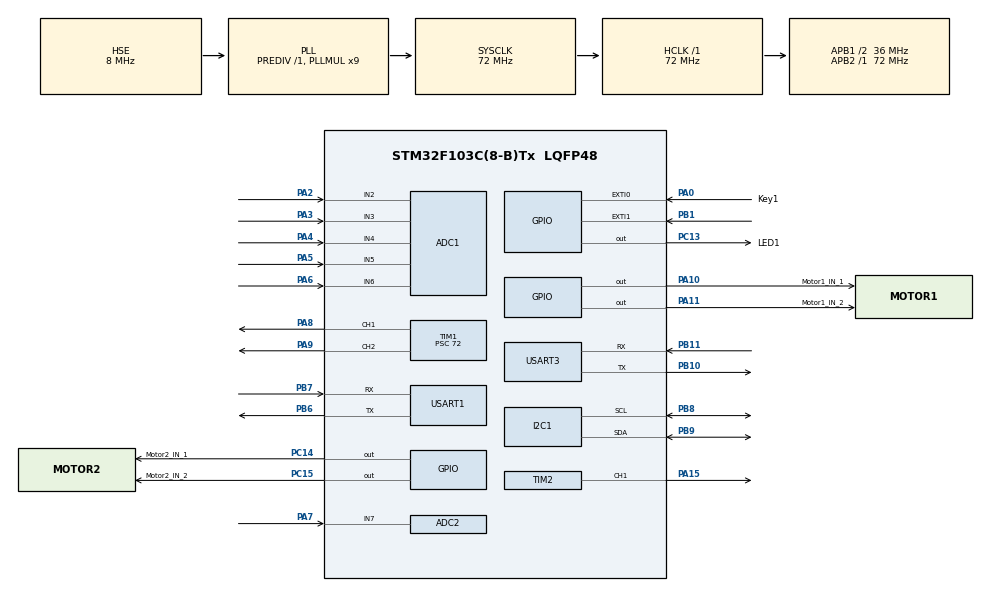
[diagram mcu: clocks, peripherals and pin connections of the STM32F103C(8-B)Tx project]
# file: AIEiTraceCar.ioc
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ADC1.Channel-1\#ChannelRegularConversion=ADC_CHANNEL_2
ADC1.Channel-2\#ChannelRegularConversion=ADC_CHANNEL_3
ADC1.Channel-3\#ChannelRegularConversion=ADC_CHANNEL_4
ADC1.Channel-4\#ChannelRegularConversion=ADC_CHANNEL_5
ADC1.Channel-5\#ChannelRegularConversion=ADC_CHANNEL_6
ADC1.ContinuousConvMode=ENABLE
ADC1.ExternalTrigConv=ADC_SOFTWARE_START
ADC1.NbrOfConversion=5
ADC1.NbrOfConversionFlag=1
ADC1.Rank-1\#ChannelRegularConversion=1
ADC1.Rank-2\#ChannelRegularConversion=2
ADC1.Rank-3\#ChannelRegularConversion=3
ADC1.Rank-4\#ChannelRegularConversion=4
ADC1.Rank-5\#ChannelRegularConversion=5
ADC1.SamplingTime-1\#ChannelRegularConversion=ADC_SAMPLETIME_1CYCLE_5
ADC1.SamplingTime-2\#ChannelRegularConversion=ADC_SAMPLETIME_1CYCLE_5
ADC1.SamplingTime-3\#ChannelRegularConversion=ADC_SAMPLETIME_1CYCLE_5
ADC1.SamplingTime-4\#ChannelRegularConversion=ADC_SAMPLETIME_1CYCLE_5
ADC1.SamplingTime-5\#ChannelRegularConversion=ADC_SAMPLETIME_1CYCLE_5
ADC1.master=1
ADC2.Channel-1\#ChannelRegularConversion=ADC_CHANNEL_7
ADC2.ContinuousConvMode=ENABLE
ADC2.NbrOfConversion=1
ADC2.NbrOfConversionFlag=1
ADC2.Rank-1\#ChannelRegularConversion=1
ADC2.SamplingTime-1\#ChannelRegularConversion=ADC_SAMPLETIME_1CYCLE_5
Dma.ADC1.1.Direction=DMA_PERIPH_TO_MEMORY
Dma.ADC1.1.Instance=DMA1_Channel1
Dma.ADC1.1.MemDataAlignment=DMA_MDATAALIGN_HALFWORD
Dma.ADC1.1.MemInc=DMA_MINC_ENABLE
Dma.ADC1.1.Mode=DMA_CIRCULAR
Dma.ADC1.1.PeriphDataAlignment=DMA_PDATAALIGN_HALFWORD
Dma.ADC1.1.PeriphInc=DMA_PINC_DISABLE
Dma.ADC1.1.Priority=DMA_PRIORITY_LOW
Dma.Request0=USART1_RX
Dma.Request1=ADC1
Dma.USART1_RX.0.Direction=DMA_PERIPH_TO_MEMORY
Dma.USART1_RX.0.Instance=DMA1_Channel5
Dma.USART1_RX.0.MemDataAlignment=DMA_MDATAALIGN_BYTE
Dma.USART1_RX.0.MemInc=DMA_MINC_ENABLE
Dma.USART1_RX.0.Mode=DMA_NORMAL
Dma.USART1_RX.0.PeriphDataAlignment=DMA_PDATAALIGN_BYTE
Dma.USART1_RX.0.PeriphInc=DMA_PINC_DISABLE
Dma.USART1_RX.0.Priority=DMA_PRIORITY_LOW
Mcu.Family=STM32F1
Mcu.Name=STM32F103C(8-B)Tx
Mcu.Package=LQFP48
NVIC.ADC1_2_IRQn=true\:0\:0\:false\:false\:true\:true\:true
NVIC.DMA1_Channel1_IRQn=true\:0\:0\:false\:false\:true\:false\:true
NVIC.DMA1_Channel5_IRQn=true\:0\:0\:false\:false\:true\:false\:true
NVIC.EXTI0_IRQn=true\:1\:0\:true\:false\:true\:true\:true
NVIC.EXTI1_IRQn=true\:0\:0\:true\:false\:true\:true\:true
NVIC.I2C1_EV_IRQn=true\:1\:0\:true\:false\:true\:true\:true
NVIC.PriorityGroup=NVIC_PRIORITYGROUP_4
NVIC.TIM3_IRQn=true\:0\:0\:true\:false\:true\:true\:true
NVIC.TIM4_IRQn=true\:0\:0\:true\:false\:true\:true\:true
NVIC.USART1_IRQn=true\:0\:0\:false\:false\:true\:true\:true
PA0-WKUP.GPIO_Label=Key1
PA0-WKUP.Signal=GPXTI0
PA10.GPIO_Label=Motor1_IN_1
PA10.Signal=GPIO_Output
PA11.GPIO_Label=Motor1_IN_2
PA11.Signal=GPIO_Output
PA13.Mode=Serial_Wire
PA13.Signal=SYS_JTMS-SWDIO
PA14.Mode=Serial_Wire
PA14.Signal=SYS_JTCK-SWCLK
PA15.Signal=S_TIM2_CH1_ETR
PA2.Signal=ADCx_IN2
PA3.Signal=ADCx_IN3
PA4.Signal=ADCx_IN4
PA5.Signal=ADCx_IN5
PA6.Signal=ADCx_IN6
PA7.Signal=ADCx_IN7
PA8.Signal=S_TIM1_CH1
PA9.Signal=S_TIM1_CH2
PB1.Signal=GPXTI1
PB10.Mode=Asynchronous
PB10.Signal=USART3_TX
PB11.Mode=Asynchronous
PB11.Signal=USART3_RX
PB6.Mode=Asynchronous
PB6.Signal=USART1_TX
PB7.Mode=Asynchronous
PB7.Signal=USART1_RX
PB8.Mode=I2C
PB8.Signal=I2C1_SCL
PB9.Mode=I2C
PB9.Signal=I2C1_SDA
PC13-TAMPER-RTC.GPIO_Label=LED1
PC13-TAMPER-RTC.Signal=GPIO_Output
PC14-OSC32_IN.GPIO_Label=Motor2_IN_1
PC14-OSC32_IN.Signal=GPIO_Output
PC15-OSC32_OUT.GPIO_Label=Motor2_IN_2
PC15-OSC32_OUT.Signal=GPIO_Output
PD0-OSC_IN.Mode=HSE-External-Oscillator
PD0-OSC_IN.Signal=RCC_OSC_IN
PD1-OSC_OUT.Mode=HSE-External-Oscillator
PD1-OSC_OUT.Signal=RCC_OSC_OUT
ProjectManager.HeapSize=0x200
ProjectManager.StackSize=0x400
ProjectManager.TargetToolchain=MDK-ARM V5.32
RCC.ADCPresc=RCC_ADCPCLK2_DIV6
RCC.AHBFreq_Value=72000000
RCC.APB1CLKDivider=RCC_HCLK_DIV2
RCC.APB1Freq_Value=36000000
RCC.APB1TimFreq_Value=72000000
RCC.APB2Freq_Value=72000000
RCC.APB2TimFreq_Value=72000000
RCC.HCLKFreq_Value=72000000
RCC.PLLMUL=RCC_PLL_MUL9
RCC.PLLSourceVirtual=RCC_PLLSOURCE_HSE
RCC.SYSCLKFreq_VALUE=72000000
RCC.SYSCLKSource=RCC_SYSCLKSOURCE_PLLCLK
RCC.USBFreq_Value=72000000
SH.ADCx_IN2.0=ADC1_IN2,IN2
SH.ADCx_IN3.0=ADC1_IN3,IN3
SH.ADCx_IN4.0=ADC1_IN4,IN4
SH.ADCx_IN5.0=ADC1_IN5,IN5
SH.ADCx_IN6.0=ADC1_IN6,IN6
SH.ADCx_IN7.0=ADC1_IN7
SH.ADCx_IN7.1=ADC2_IN7,IN7
SH.S_TIM1_CH1.0=TIM1_CH1,PWM Generation1 CH1
SH.S_TIM1_CH2.0=TIM1_CH2,PWM Generation2 CH2
SH.S_TIM2_CH1_ETR.0=TIM2_CH1,PWM Generation1 CH1
TIM1.Channel-PWM\ Generation1\ CH1=TIM_CHANNEL_1
TIM1.Channel-PWM\ Generation2\ CH2=TIM_CHANNEL_2
TIM1.Period=9999
TIM1.Prescaler=72
TIM1.Pulse-PWM\ Generation1\ CH1=5000
TIM1.Pulse-PWM\ Generation2\ CH2=5000
TIM2.Channel-PWM\ Generation1\ CH1=TIM_CHANNEL_1
TIM2.Period=9999
TIM2.Prescaler=71
TIM2.Pulse-PWM\ Generation1\ CH1=250
TIM3.Period=5000
TIM3.Prescaler=72
TIM3.TIM_MasterOutputTrigger=TIM_TRGO_UPDATE
TIM4.Period=30000
TIM4.Prescaler=72
USART1.VirtualMode=VM_ASYNC
USART3.VirtualMode=VM_ASYNC
VP_TIM1_VS_ClockSourceINT.Mode=Internal
VP_TIM2_VS_ClockSourceINT.Mode=Internal
VP_TIM3_VS_ClockSourceINT.Mode=Internal
VP_TIM4_VS_ClockSourceINT.Mode=Internal
board=custom

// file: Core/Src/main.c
/* USER CODE BEGIN Header */
/**
  ******************************************************************************
  * @file           : main.c
  * @brief          : Main program body
  ******************************************************************************
  * @attention
  *
  * Copyright (c) 2022 STMicroelectronics.
  * All rights reserved.
  *
  * This software is licensed under terms that can be found in the LICENSE file
  * in the root directory of this software component.
  * If no LICENSE file comes with this software, it is provided AS-IS.
  *
  ******************************************************************************
  */
/* USER CODE END Header */
#include "main.h"
#include "adc.h"
#include "dma.h"
#include "i2c.h"
#include "tim.h"
#include "usart.h"
#include "gpio.h"

/* USER CODE BEGIN Includes */
#include "bspCSIS.h"
/* USER CODE END Includes */

void SystemClock_Config(void);

int main(void)
{

  /* MCU Configuration--------------------------------------------------------*/

  /* Reset of all peripherals, Initializes the Flash interface and the Systick. */
  HAL_Init();

  /* Configure the system clock */
  SystemClock_Config();

  /* Initialize all configured peripherals */
  MX_GPIO_Init();
	MX_DMA_Init();
  MX_ADC1_Init();
  MX_ADC2_Init();
  MX_I2C1_Init();
  MX_TIM1_Init();
  MX_TIM2_Init();
  MX_TIM3_Init();
  MX_USART1_UART_Init();
  MX_USART3_UART_Init();
  MX_TIM4_Init();
  /* USER CODE BEGIN 2 */
	bsp_GloableInit();
  /* USER CODE END 2 */

  /* Infinite loop */
  /* USER CODE BEGIN WHILE */
  while (1)
  {
		bsp_OLED_Display();
		bsp_Usart_Receive();
		bsp_Emac_Operate();
		bsp_LED_FeedBack();

    /* USER CODE END WHILE */

  }
}

void SystemClock_Config(void)
{
  RCC_OscInitTypeDef RCC_OscInitStruct = {0};
  RCC_ClkInitTypeDef RCC_ClkInitStruct = {0};
  RCC_PeriphCLKInitTypeDef PeriphClkInit = {0};

  /** Initializes the RCC Oscillators according to the specified parameters
  * in the RCC_OscInitTypeDef structure.
  */
  RCC_OscInitStruct.OscillatorType = RCC_OSCILLATORTYPE_HSE;
  RCC_OscInitStruct.HSEState = RCC_HSE_ON;
  RCC_OscInitStruct.HSEPredivValue = RCC_HSE_PREDIV_DIV1;
  RCC_OscInitStruct.HSIState = RCC_HSI_ON;
  RCC_OscInitStruct.PLL.PLLState = RCC_PLL_ON;
  RCC_OscInitStruct.PLL.PLLSource = RCC_PLLSOURCE_HSE;
  RCC_OscInitStruct.PLL.PLLMUL = RCC_PLL_MUL9;
  if (HAL_RCC_OscConfig(&RCC_OscInitStruct) != HAL_OK)
  {
    Error_Handler();
  }
  /** Initializes the CPU, AHB and APB buses clocks
  */
  RCC_ClkInitStruct.ClockType = RCC_CLOCKTYPE_HCLK|RCC_CLOCKTYPE_SYSCLK
                              |RCC_CLOCKTYPE_PCLK1|RCC_CLOCKTYPE_PCLK2;
  RCC_ClkInitStruct.SYSCLKSource = RCC_SYSCLKSOURCE_PLLCLK;
  RCC_ClkInitStruct.AHBCLKDivider = RCC_SYSCLK_DIV1;
  RCC_ClkInitStruct.APB1CLKDivider = RCC_HCLK_DIV2;
  RCC_ClkInitStruct.APB2CLKDivider = RCC_HCLK_DIV1;

  if (HAL_RCC_ClockConfig(&RCC_ClkInitStruct, FLASH_LATENCY_2) != HAL_OK)
  {
    Error_Handler();
  }
  PeriphClkInit.PeriphClockSelection = RCC_PERIPHCLK_ADC;
  PeriphClkInit.AdcClockSelection = RCC_ADCPCLK2_DIV6;
  if (HAL_RCCEx_PeriphCLKConfig(&PeriphClkInit) != HAL_OK)
  {
    Error_Handler();
  }
}

void Error_Handler(void)
{
  __disable_irq();
  while (1)
  {
  }
}
